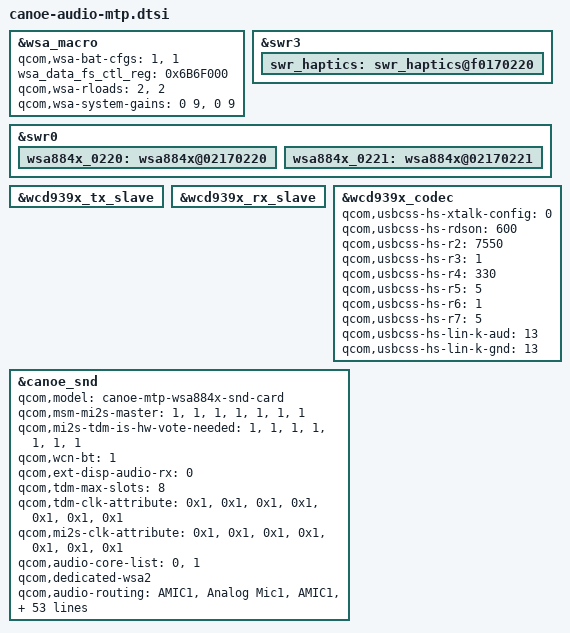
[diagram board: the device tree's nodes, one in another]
//
/* Copyright (c) Qualcomm Technologies, Inc. and/or its subsidiaries.
 *  SPDX-License-Identifier: BSD-3-Clause-Clear
 */

#include "lpass-audio-cdc-1.0.dtsi"
#include "canoe-lpi.dtsi"
#include "lpass-audio-bt-swr.dtsi"
#include "lpass-cdc-gpio.dtsi"
#include "canoe-audio-lpass-reg.dtsi"
#include "wsa884x.dtsi"
#include "wcd939x.dtsi"

&wsa_macro {
	qcom,wsa-bat-cfgs= <1>, <1>;
	wsa_data_fs_ctl_reg = <0x6B6F000>;
	qcom,wsa-bat-cfgs= <1>, <1>;
	qcom,wsa-rloads= <2>, <2>;
	qcom,wsa-system-gains= <0 9>, <0 9>;
};

&swr3 {
	swr_haptics: swr_haptics@f0170220 {
		status = "okay";
	};
};

&swr0 {
	wsa884x_0220: wsa884x@02170220 {
		status = "okay";
	};

	wsa884x_0221: wsa884x@02170221 {
		status = "okay";
	};
};

&wcd939x_tx_slave {
	status = "okay";
};

&wcd939x_rx_slave {
	status = "okay";
};

&wcd939x_codec {
	status = "okay";
	/* 0 for digital crosstalk disabled,
	 * 1 for digital crosstalk with local sensed a-xtalk enabled, and
	 * 2 for digital crosstalk with remote sensed a-xtalk enabled.
	 */
	qcom,usbcss-hs-xtalk-config = <0>;
	qcom,usbcss-hs-rdson = <600>;
	qcom,usbcss-hs-r2 = <7550>;
	qcom,usbcss-hs-r3 = <1>;
	qcom,usbcss-hs-r4 = <330>;
	qcom,usbcss-hs-r5 = <5>;
	qcom,usbcss-hs-r6 = <1>;
	qcom,usbcss-hs-r7 = <5>;
	qcom,usbcss-hs-lin-k-aud = <13>;
	qcom,usbcss-hs-lin-k-gnd = <13>;
};


&canoe_snd {
		qcom,model = "canoe-mtp-wsa884x-snd-card";
		qcom,msm-mi2s-master = <1>, <1>, <1>, <1>, <1>, <1>, <1>;
		qcom,mi2s-tdm-is-hw-vote-needed = <1>, <1>, <1>, <1>, <1>, <1>, <1>;
		qcom,wcn-bt = <1>;
		qcom,ext-disp-audio-rx = <0>;
		qcom,tdm-max-slots = <8>;
		qcom,tdm-clk-attribute = <0x1>, <0x1>, <0x1>, <0x1>, <0x1>, <0x1>, <0x1>;
		qcom,mi2s-clk-attribute = <0x1>, <0x1>, <0x1>, <0x1>, <0x1>, <0x1>, <0x1>;
		qcom,audio-core-list = <0>, <1>;
		/*
		 * Add this property,
		 * To Enable swr haptics through OPCM port.
		 * This will include wsa2 dailinks.
		 */
		qcom,dedicated-wsa2;
		qcom,audio-routing =
			"AMIC1", "Analog Mic1",
			"AMIC1", "MIC BIAS1",
			"AMIC2", "Analog Mic2",
			"AMIC2", "MIC BIAS2",
			"AMIC3", "Analog Mic3",
			"AMIC3", "MIC BIAS3",
			"AMIC4", "Analog Mic4",
			"AMIC4", "MIC BIAS3",
			"AMIC5", "Analog Mic5",
			"AMIC5", "MIC BIAS4",
			"VA AMIC1", "Analog Mic1",
			"VA AMIC1", "VA MIC BIAS1",
			"VA AMIC2", "Analog Mic2",
			"VA AMIC2", "VA MIC BIAS2",
			"VA AMIC3", "Analog Mic3",
			"VA AMIC3", "VA MIC BIAS3",
			"VA AMIC4", "Analog Mic4",
			"VA AMIC4", "VA MIC BIAS3",
			"VA AMIC5", "Analog Mic5",
			"VA AMIC5", "VA MIC BIAS4",
			"TX DMIC0", "Digital Mic0",
			"TX DMIC0", "MIC BIAS1",
			"TX DMIC1", "Digital Mic1",
			"TX DMIC1", "MIC BIAS1",
			"TX DMIC2", "Digital Mic2",
			"TX DMIC2", "MIC BIAS3",
			"TX DMIC3", "Digital Mic3",
			"TX DMIC3", "MIC BIAS3",
			"IN1_HPHL", "HPHL_OUT",
			"IN2_HPHR", "HPHR_OUT",
			"IN3_EAR", "AUX_OUT",
			"HAP_IN", "WSA2_HAPT OUT",
			"WSA SRC0_INP", "SRC0",
			"WSA_TX DEC0_INP", "TX DEC0 MUX",
			"WSA_TX DEC1_INP", "TX DEC1 MUX",
			"RX_TX DEC0_INP", "TX DEC0 MUX",
			"RX_TX DEC1_INP", "TX DEC1 MUX",
			"RX_TX DEC2_INP", "TX DEC2 MUX",
			"RX_TX DEC3_INP", "TX DEC3 MUX",
			"SpkrLeft IN", "WSA_SPK1 OUT",
			"SpkrRight IN", "WSA_SPK2 OUT",
			"TX SWR_INPUT", "WCD_TX_OUTPUT",
			"VA SWR_INPUT", "VA_SWR_CLK",
			"VA SWR_INPUT", "WCD_TX_OUTPUT",
			"VA_AIF1 CAP", "VA_SWR_CLK",
			"VA_AIF2 CAP", "VA_SWR_CLK",
			"VA_AIF3 CAP", "VA_SWR_CLK",
			"VA DMIC0", "Digital Mic0",
			"VA DMIC1", "Digital Mic1",
			"VA DMIC2", "Digital Mic2",
			"VA DMIC3", "Digital Mic3",
			"VA DMIC0", "VA MIC BIAS1",
			"VA DMIC1", "VA MIC BIAS1",
			"VA DMIC2", "VA MIC BIAS3",
			"VA DMIC3", "VA MIC BIAS3";
		qcom,msm-mbhc-hs-mic-max-threshold-mv = <1670>;
		qcom,msm-mbhc-usbc-audio-supported = <1>;
		qcom,msm-mbhc-hphl-swh = <0>;
		qcom,msm-mbhc-gnd-swh = <0>;
		wcd939x-i2c-handle = <&wcd_usbss>;

		qcom,cdc-dmic01-gpios = <&cdc_dmic01_gpios>;
		qcom,cdc-dmic23-gpios = <&cdc_dmic23_gpios>;
		qcom,cdc-dmic45-gpios = <&cdc_dmic45_gpios>;
		asoc-codec  = <&stub_codec>, <&lpass_cdc>,
			      <&wcd939x_codec>, <&swr_haptics>,
			      <&wsa884x_0220>, <&wsa884x_0221>;
		asoc-codec-names = "msm-stub-codec.1", "lpass-cdc",
				"wcd939x_codec", "swr-haptics",
				"wsa-codec1", "wsa-codec2";
		qcom,wsa-max-devs = <2>;
		qcom,msm_audio_ssr_devs = <&audio_gpr>, <&lpi_tlmm>,
				<&lpass_cdc>, <&lpass_bt_swr>;

		/*
		 * ====================
		 * UPD backend - WSA
		 * ====================
		 *
		 * Mute/Unmute the interpolator
		 * ------------------------------
		 * Register: LPASS_WSA_CDC_RX0_RX_PATH_MIX_CTL - 0x6B00418
		 *
		 * Send control commands to the peripheral from the soundwire controller
		 * -----------------------------------------------------------------------
		 * Register: LPASS_WSA_SWR_MSTR_WSA_SWRM_CPUn_CMD_FIFO_WR_CMD - 0x6B14020
		 *
		 * Enable/Disable ear piece
		 * --------------------------
		 * Register: DIG_CTRL0_PA_FSM_EN - 0x3430
		 *
		 */
		qcom,upd_backends_used = "wsa";
		qcom,upd_lpass_reg_addr = <0x6B00418 0x6B14020>;
		qcom,upd_ear_pa_reg_addr = <0x3430>;

		/*
		 * ====================
		 * UPD backend - WCD
		 * ====================
		 *
		 * Mute/Unmute the interpolator
		 * ------------------------------
		 * Register: LPASS_WCD_CDC_RX0_RX_PATH_MIX_CTL - 0x6AC0418
		 *
		 * Send control commands to the wcd from the soundwire controller
		 * ----------------------------------------------------------------
		 * Register: LPASS_WCD_SWR_MSTR_WSA_SWRM_CPUn_CMD_FIFO_WR_CMD - 0x7634020
		 *
		 * Enable/Disable ear piece
		 * --------------------------
		 * Register: DIG_CTRL0_PA_FSM_EN - 0x300A
		 *
		 * qcom,upd_backends_used = "wcd";
		 * qcom,upd_lpass_reg_addr = <0x6AC0418 0x7634020>;
		 * qcom,upd_ear_pa_reg_addr = <0x300A>;
		 */

};
